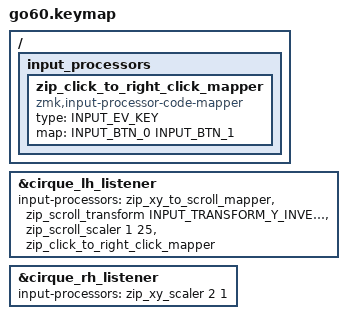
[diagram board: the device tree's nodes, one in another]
//
////
////////
////////////////
////////////////////////////////
////////////////////////////////////////////////////////////////

#include "moergo_includes.h"

#define MOERGO_DEVICE MOERGO_DEVICE_GO60

////////////////////////////////////////////////////////////////

#define LC1 -1  // left-ceiling row
#define LC2 -1
#define LC3 -1
#define LC4 -1
#define LC5 -1

#define RC1 -1  // right-ceiling row
#define RC2 -1
#define RC3 -1
#define RC4 -1
#define RC5 -1

#define POS_LH_C6R1 0
#define POS_LH_C5R1 1
#define POS_LH_C4R1 2
#define POS_LH_C3R1 3
#define POS_LH_C2R1 4
#define POS_LH_C1R1 5

#define POS_RH_C1R1 6
#define POS_RH_C2R1 7
#define POS_RH_C3R1 8
#define POS_RH_C4R1 9
#define POS_RH_C5R1 10
#define POS_RH_C6R1 11

#define LN0 5  // left-number row
#define LN1 4
#define LN2 3
#define LN3 2
#define LN4 1
#define LN5 0

#define RN0 6  // right-number row
#define RN1 7
#define RN2 8
#define RN3 9
#define RN4 10
#define RN5 11

#define POS_LH_C6R2 12
#define POS_LH_C5R2 13
#define POS_LH_C4R2 14
#define POS_LH_C3R2 15
#define POS_LH_C2R2 16
#define POS_LH_C1R2 17

#define POS_RH_C1R2 18
#define POS_RH_C2R2 19
#define POS_RH_C3R2 20
#define POS_RH_C4R2 21
#define POS_RH_C5R2 22
#define POS_RH_C6R2 23

#define LT0 17  // left-top row
#define LT1 16
#define LT2 15
#define LT3 14
#define LT4 13
#define LT5 12

#define RT0 18 // right-top row
#define RT1 19
#define RT2 20
#define RT3 21
#define RT4 22
#define RT5 23

#define POS_LH_C6R3 24
#define POS_LH_C5R3 25
#define POS_LH_C4R3 26
#define POS_LH_C3R3 27
#define POS_LH_C2R3 28
#define POS_LH_C1R3 29

#define POS_RH_C1R3 30
#define POS_RH_C2R3 31
#define POS_RH_C3R3 32
#define POS_RH_C4R3 33
#define POS_RH_C5R3 34
#define POS_RH_C6R3 35

#define LM0 29  // left-middle row
#define LM1 28
#define LM2 27
#define LM3 26
#define LM4 25
#define LM5 24

#define RM0 30  // right-middle row
#define RM1 31
#define RM2 32
#define RM3 33
#define RM4 34
#define RM5 35

#define POS_LH_C6R4 36
#define POS_LH_C5R4 37
#define POS_LH_C4R4 38
#define POS_LH_C3R4 39
#define POS_LH_C2R4 40
#define POS_LH_C1R4 41

#define POS_RH_C1R4 42
#define POS_RH_C2R4 43
#define POS_RH_C3R4 44
#define POS_RH_C4R4 45
#define POS_RH_C5R4 46
#define POS_RH_C6R4 47

#define LB0 41  // left-bottom row
#define LB1 40
#define LB2 39
#define LB3 38
#define LB4 37
#define LB5 36

#define RB0 42  // right-bottom row
#define RB1 43
#define RB2 44
#define RB3 45
#define RB4 46
#define RB5 47

#define POS_LH_C4R5 48
#define POS_LH_C3R5 49
#define POS_LH_C2R5 50

#define POS_RH_C2R5 51
#define POS_RH_C3R5 52
#define POS_RH_C4R5 53

#define LF1 50  // left-floor row
#define LF2 49
#define LF3 48
#define LF4 -1
#define LF5 -1

#define RF1 51  // right-floor row
#define RF2 52
#define RF3 53
#define RF4 -1
#define RF5 -1

#define POS_LH_T1 54
#define POS_LH_T2 55
#define POS_LH_T3 56

#define POS_RH_T3 57
#define POS_RH_T2 58
#define POS_RH_T1 59

#define LH0 -1  // left thumb keys
#define LH1 -1
#define LH2 56
#define LH3 -1
#define LH4 55
#define LH5 54

#define RH0 -1  // right thumb keys
#define RH1 -1
#define RH2 57
#define RH3 -1
#define RH4 58
#define RH5 59

////////////////////////////////////////////////////////////////

#define LEFT_HAND_KEYS \
  POS_LH_C1R1 POS_LH_C2R1 POS_LH_C3R1 POS_LH_C4R1 POS_LH_C5R1 POS_LH_C6R1 \
  POS_LH_C1R2 POS_LH_C2R2 POS_LH_C3R2 POS_LH_C4R2 POS_LH_C5R2 POS_LH_C6R2 \
  POS_LH_C1R3 POS_LH_C2R3 POS_LH_C3R3 POS_LH_C4R3 POS_LH_C5R3 POS_LH_C6R3 \
  POS_LH_C1R4 POS_LH_C2R4 POS_LH_C3R4 POS_LH_C4R4 POS_LH_C5R4 POS_LH_C6R4 \
              POS_LH_C2R5 POS_LH_C3R5 POS_LH_C4R5

#define RIGHT_HAND_KEYS \
  POS_RH_C1R1 POS_RH_C2R1 POS_RH_C3R1 POS_RH_C4R1 POS_RH_C5R1 POS_RH_C6R1 \
  POS_RH_C1R2 POS_RH_C2R2 POS_RH_C3R2 POS_RH_C4R2 POS_RH_C5R2 POS_RH_C6R2 \
  POS_RH_C1R3 POS_RH_C2R3 POS_RH_C3R3 POS_RH_C4R3 POS_RH_C5R3 POS_RH_C6R3 \
  POS_RH_C1R4 POS_RH_C2R4 POS_RH_C3R4 POS_RH_C4R4 POS_RH_C5R4 POS_RH_C6R4 \
              POS_RH_C2R5 POS_RH_C3R5 POS_RH_C4R5

#define LEFT_THUMB_KEYS \
  POS_LH_T1 POS_LH_T2 POS_LH_T3

#define RIGHT_THUMB_KEYS \
  POS_RH_T1 POS_RH_T2 POS_RH_T3

#define THUMB_KEYS \
  LEFT_THUMB_KEYS RIGHT_THUMB_KEYS

////////////////////////////////

#define KEYS_FINGERS_LEFT LEFT_HAND_KEYS
#define KEYS_FINGERS_RIGHT RIGHT_HAND_KEYS
#define KEYS_THUMB_LEFT LEFT_THUMB_KEYS
#define KEYS_THUMB_RIGHT RIGHT_THUMB_KEYS
#define KEYS_THUMB_LEFT_AND_RIGHT THUMB_KEYS

////////////////////////////////////////////////////////////////
// https://github.com/moergo-keyboards/go60-zmk-config/blob/main/config/go60.keymap

/*
/ {
    behaviors {
        magic: magic {
            compatible = "zmk,behavior-hold-tap";
            #binding-cells = <2>;
            flavor = "tap-preferred";
            tapping-term-ms = <200>;
            bindings = <&mo>, <&rgb_ug_status_macro>;
        };

        bt_0: bt_0 {
            compatible = "zmk,behavior-tap-dance";
            #binding-cells = <0>;
            tapping-term-ms = <200>;
            bindings = <&bt_select_0>, <&bt BT_DISC 0>;
        };
        bt_1: bt_1 {
            compatible = "zmk,behavior-tap-dance";
            #binding-cells = <0>;
            tapping-term-ms = <200>;
            bindings = <&bt_select_1>, <&bt BT_DISC 1>;
        };
        bt_2: bt_2 {
            compatible = "zmk,behavior-tap-dance";
            #binding-cells = <0>;
            tapping-term-ms = <200>;
            bindings = <&bt_select_2>, <&bt BT_DISC 2>;
        };
        bt_3: bt_3 {
            compatible = "zmk,behavior-tap-dance";
            #binding-cells = <0>;
            tapping-term-ms = <200>;
            bindings = <&bt_select_3>, <&bt BT_DISC 3>;
        };
    };

    macros {
        rgb_ug_status_macro: rgb_ug_status_macro {
            compatible = "zmk,behavior-macro";
            #binding-cells = <0>;
            bindings = <&rgb_ug RGB_STATUS>;
        };

        bt_select_0: bt_select_0 {
            compatible = "zmk,behavior-macro";
            #binding-cells = <0>;
            bindings
                = <&out OUT_BLE>,
                  <&bt BT_SEL 0>;
        };
        bt_select_1: bt_select_1 {
            compatible = "zmk,behavior-macro";
            #binding-cells = <0>;
            bindings
                = <&out OUT_BLE>,
                  <&bt BT_SEL 1>;
        };
        bt_select_2: bt_select_2 {
            compatible = "zmk,behavior-macro";
            #binding-cells = <0>;
            bindings
                = <&out OUT_BLE>,
                  <&bt BT_SEL 2>;
        };
        bt_select_3: bt_select_3 {
            compatible = "zmk,behavior-macro";
            #binding-cells = <0>;
            bindings
                = <&out OUT_BLE>,
                  <&bt BT_SEL 3>;
        };
    };
};

#define KEYMAP_LAYER_FACTORY \
ZMK_LAYER(factory, \
 &kp N0  &kp N4  &kp N8  &kp N3  &kp N8  &kp N3                                                  &kp N3  &kp N8  &kp N3  &kp N8  &kp N4  &kp N0 \
 &kp N1  &kp N5  &kp N9  &kp N4  &kp N9  &kp N4                                                  &kp N4  &kp N9  &kp N4  &kp N9  &kp N5  &kp N1 \
 &kp N2  &kp N6  &kp N0  &kp N5  &kp N0  &kp N5                                                  &kp N5  &kp N0  &kp N5  &kp N0  &kp N6  &kp N2 \
 &kp N3  &kp N7  &kp N1  &kp N6  &kp N1  &kp N6                                                  &kp N6  &kp N1  &kp N6  &kp N1  &kp N7  &kp N3 \
                 &kp N2  &kp N7  &kp N2                                                                  &kp N2  &kp N7  &kp N2 \
                                                 &kp N7  &kp N8  &kp N9  &kp N9  &kp N8  &kp N7 \
)

#if 1
#define KEYMAP_LAYER_MAGIC \
    KEYMAP_LAYER_FACTORY
#else // compile error: parse error: expected number or parenthesized expression
#define LAYER_MAGIC \
ZMK_LAYER(magic, \
        &bt BT_CLR      &kp C_BRI_DN     &kp C_BRI_UP     &kp C_PREV       &kp C_NEXT       &kp C_PP           &kp C_MUTE    &kp C_VOL_DN   &kp C_VOL_UP    &none  &none  &bt BT_CLR_ALL     \
        &bootloader     &rgb_ug RGB_SPI  &rgb_ug RGB_SAI  &rgb_ug RGB_HUI  &rgb_ug RGB_BRI  &rgb_ug RGB_TOG    &none         &none          &none           &none  &none  &bootloader         \
        &sys_reset      &rgb_ug RGB_SPD  &rgb_ug RGB_SAD  &rgb_ug RGB_HUD  &rgb_ug RGB_BRD  &rgb_ug RGB_EFF    &none         &none          &none           &none  &none  &sys_reset          \
        &none           &none            &bt_0            &bt_1            &bt_2            &bt_3              &none         &none          &none           &none  &none  &to LAYER_Factory   \
        &out OUT_USB    &none            &none            &none            &none            &none              \
        &none           &none            &none            &none            &none            &none              \
)
#endif

*/

////////////////////////////////////////////////////////////////

#define MOERGO_LAYER( \
            name, \
            cl, cr, \
            nl, nr, \
            tl, tr, \
            ml, mr, \
            bl, br, \
            flb, fla, fra, frb, \
            th0la, th0lb, th0rb, th0ra, \
            th1la, th1lb, th1rb, th1ra \
        ) \
        ZMK_LAYER( \
            name, \
            nl nr tl tr ml mr bl br \
            fla fra \
            th1la th0la th0ra th1ra \
        )


////////////////////////////////////////////////////////////////

#include "moergo.keymap"

////////////////////////////////////////////////////////////////
// https://zmk.dev/docs/keymaps/input-processors

#include <dt-bindings/zmk/input_transform.h>
#include <dt-bindings/zmk/pointing.h>
#include <input/processors.dtsi>
#include <zephyr/dt-bindings/input/input-event-codes.h>

////////////////////////////////

/ {
    input_processors {
        zip_click_to_right_click_mapper: zip_click_to_right_click_mapper {
            compatible = "zmk,input-processor-code-mapper";
            #input-processor-cells = <0>;
            type = <INPUT_EV_KEY>;
            map = <INPUT_BTN_0 INPUT_BTN_1>;
        };
    };
};

////////////////////////////////

&cirque_lh_listener {
    input-processors = \
        <&zip_xy_to_scroll_mapper>, \
        <&zip_scroll_transform INPUT_TRANSFORM_Y_INVERT>, \
        <&zip_scroll_scaler 1 25>, \
        <&zip_click_to_right_click_mapper>;
};

&cirque_rh_listener {
    input-processors = \
        <&zip_xy_scaler 2 1>;
};

////////////////////////////////////////////////////////////////
////////////////////////////////
////////////////
////////
////
//
